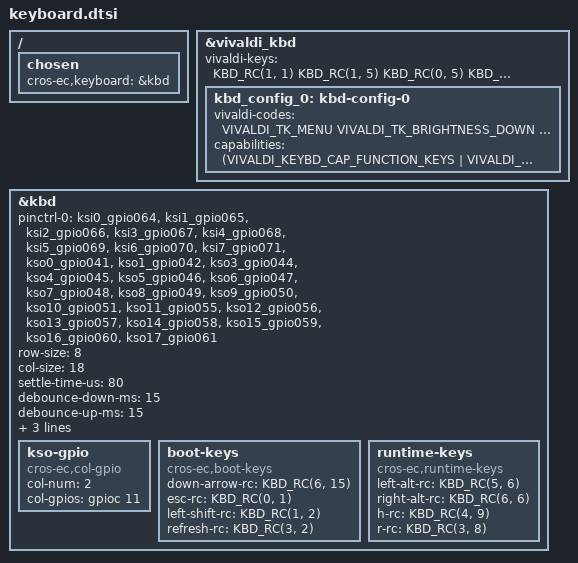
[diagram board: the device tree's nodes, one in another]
/* Copyright 2025 The ChromiumOS Authors
 * Use of this source code is governed by a BSD-style license that can be
 * found in the LICENSE file.
 */

/ {
	chosen {
		cros-ec,keyboard = &kbd;
	};
};

&vivaldi_kbd {
	vivaldi-keys = <
		KBD_RC(1, 1)    /* T1 */
		KBD_RC(1, 5)    /* T2 */
		KBD_RC(0, 5)    /* T3 */
		KBD_RC(1, 7)    /* T4 */
		KBD_RC(0, 7)    /* T5 */
		KBD_RC(0, 8)    /* T6 */
		KBD_RC(0, 9)    /* T7 */
		KBD_RC(1, 10)   /* T8 */
		KBD_RC(0, 10)   /* T9 */
		KBD_RC(0, 12)   /* T10 */
		KBD_RC(0, 13)   /* T11 */
		KBD_RC(1, 13)   /* T12 */
		KBD_RC(1, 15)   /* T13 */
		KBD_RC(7, 11)   /* T14 */
		KBD_RC(0, 14)   /* T15 */
 	>;

	kbd_config_0: kbd-config-0{
		vivaldi-codes = <
			VIVALDI_TK_MENU                 /* T1 */
			VIVALDI_TK_BRIGHTNESS_DOWN      /* T2 */
			VIVALDI_TK_BRIGHTNESS_UP        /* T3 */
			VIVALDI_TK_FULLSCREEN           /* T4 */
			VIVALDI_TK_OVERVIEW             /* T5 */
			VIVALDI_TK_VOL_MUTE             /* T6 */
			VIVALDI_TK_VOL_DOWN             /* T7 */
			VIVALDI_TK_VOL_UP               /* T8 */
			VIVALDI_TK_FORWARD              /* T9 */
			VIVALDI_TK_SNAPSHOT             /* T10 */
			VIVALDI_TK_MICMUTE              /* T11 */
			VIVALDI_TK_PREV_TRACK           /* T12 */
			VIVALDI_TK_PLAY_PAUSE           /* T13 */
			VIVALDI_TK_NEXT_TRACK           /* T14 */
			VIVALDI_TK_BACK                 /* T15 */
		>;
		capabilities = < (VIVALDI_KEYBD_CAP_FUNCTION_KEYS |
				VIVALDI_KEYBD_CAP_SCRNLOCK_KEY |
				VIVALDI_KEYBD_CAP_NUMERIC_KEYPAD |
				VIVALDI_KEYBD_CAP_ASSISTANT_KEY) >;
	};
};

&kbd {
	status = "okay";
	/* No KSO2 (it's inverted and implemented by GPIO) */
	pinctrl-0 = <
		&ksi0_gpio064
		&ksi1_gpio065
		&ksi2_gpio066
		&ksi3_gpio067
		&ksi4_gpio068
		&ksi5_gpio069
		&ksi6_gpio070
		&ksi7_gpio071
		&kso0_gpio041
		&kso1_gpio042
		&kso3_gpio044
		&kso4_gpio045
		&kso5_gpio046
		&kso6_gpio047
		&kso7_gpio048
		&kso8_gpio049
		&kso9_gpio050
		&kso10_gpio051
		&kso11_gpio055
		&kso12_gpio056
		&kso13_gpio057
		&kso14_gpio058
		&kso15_gpio059
		&kso16_gpio060
		&kso17_gpio061
	>;

	pinctrl-names = "default";
	row-size = <8>;
	col-size = <18>;
	settle-time-us = <80>;
	debounce-down-ms = <15>;
	debounce-up-ms = <15>;
	actual-key-mask = <0x9b 0xff 0x5f 0x9f 0x08 0xff 0x7b 0xff
			   0xff 0xff 0xff 0xff 0xff 0xff 0xff 0xff 0xff 0xff>;
	kso-ignore-mask = <04>;

	kso-gpio {
		compatible = "cros-ec,col-gpio";
		col-num = <2>;
		col-gpios = <&gpioc 11 GPIO_ACTIVE_HIGH>;
	};

	boot-keys {
		compatible = "cros-ec,boot-keys";
		down-arrow-rc = <KBD_RC(6, 15)>;
		esc-rc = <KBD_RC(0, 1)>;
		left-shift-rc = <KBD_RC(1, 2)>;
		refresh-rc = <KBD_RC(3, 2)>;
	};

	runtime-keys {
		compatible = "cros-ec,runtime-keys";
		left-alt-rc = <KBD_RC(5, 6)>;
		right-alt-rc = <KBD_RC(6, 6)>;
		h-rc = <KBD_RC(4, 9)>;
		r-rc = <KBD_RC(3, 8)>;
	};
};
